# thuasrv32 register map
Vendor: jesseopdenbrouw; Series: RISC-V; File version: 0.4.1
CPU: THUASRV32 r2p1, little endian, no MPU, no FPU, 4 interrupt priority bits
Registers are 32-bit, read-write, no defined reset value unless marked. A register's access mark holds for its fields unless they carry their own. Offsets are from the block's base; [hi:lo] are bit positions.

## MSI — Machine Software Interrupt
Base 0xF0000900
0x00 TRIG — Trigger Register
  [0] MSI_TRIG — MSI Trigger Field

## SPI1 — Serial Peripheral interface 1
Base 0xF0000400
Same registers: SPI2 0xF0000500
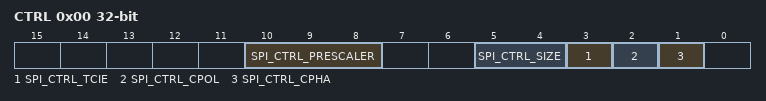
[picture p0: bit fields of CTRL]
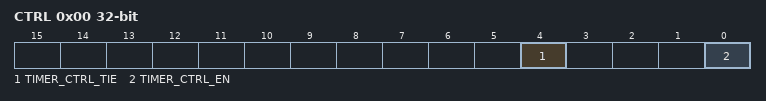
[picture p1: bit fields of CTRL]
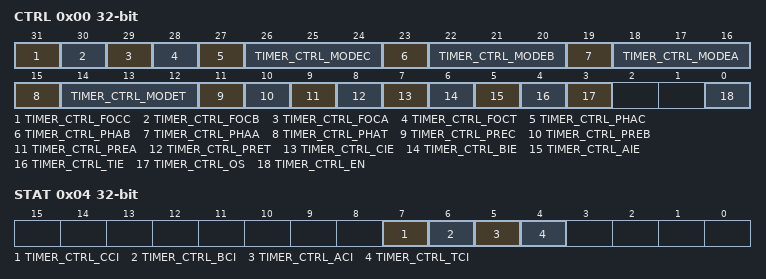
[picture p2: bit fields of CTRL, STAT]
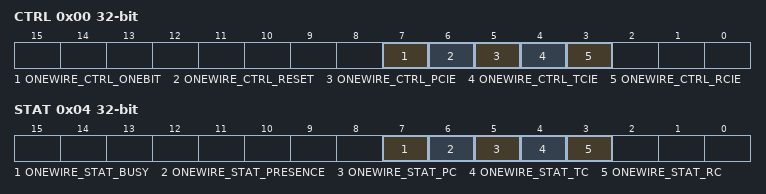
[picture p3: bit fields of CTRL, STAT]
0x00 CTRL — Control Register
  [10:8] SPI_CTRL_PRESCALER — SPI Prescaler
  [5:4] SPI_CTRL_SIZE — SPI Transmission Size
  [3] SPI_CTRL_TCIE — SPI Transmission Complete Interrupt Enable
  [2] SPI_CTRL_CPOL — SPI Clock Polarity
  [1] SPI_CTRL_CPHA — SPI Clock Phase
0x04 STAT — Status Register
  [3] SPI_STAT_TC — SPI Transmission Complete
0x08 DATA
  [31:0] SPI_DATA_DATA — SPI Data Field

## TIMER1
Base 0xF0000600
0x00 CTRL — Control Register
  [4] TIMER_CTRL_TIE — Timer 1 Compare Match Interrupt Enable
  [0] TIMER_CTRL_EN — Timer 1 Enable
0x04 STAT — Status Register
  [4] TIMER_STAT_TCI — Timer 1 Compare Match Interrupt
0x08 CNTR — Counter Register
0x0C CMPT — Compare Match T register

## TIMER2
Base 0xF0000700
0x00 CTRL — Control Register
  [31] TIMER_CTRL_FOCC — Timer 2 Force Compare Match C
  [30] TIMER_CTRL_FOCB — Timer 2 Force Compare Match B
  [29] TIMER_CTRL_FOCA — Timer 2 Force Compare Match A
  [28] TIMER_CTRL_FOCT — Timer 2 Force Compare Match T
  [27] TIMER_CTRL_PHAC — Timer 2 C Phase
  [26:24] TIMER_CTRL_MODEC — Timer 2 C Mode Field
  [23] TIMER_CTRL_PHAB — Timer 2 B Phase
  [22:20] TIMER_CTRL_MODEB — Timer 2 B Mode Field
  [19] TIMER_CTRL_PHAA — Timer 2 A Phase
  [18:16] TIMER_CTRL_MODEA — Timer 2 A Mode Field
  [15] TIMER_CTRL_PHAT — Timer 2 T Phase
  [14:12] TIMER_CTRL_MODET — Timer 2 T Mode Field
  [11] TIMER_CTRL_PREC — Timer 2 Preload C Enable
  [10] TIMER_CTRL_PREB — Timer 2 Preload B Enable
  [9] TIMER_CTRL_PREA — Timer 2 Preload A Enable
  [8] TIMER_CTRL_PRET — Timer 2 Preload T Enable
  [7] TIMER_CTRL_CIE — Timer 2 Compare Match C Interrupt Enable
  [6] TIMER_CTRL_BIE — Timer 2 Compare Match B Interrupt Enable
  [5] TIMER_CTRL_AIE — Timer 2 Compare Match A Interrupt Enable
  [4] TIMER_CTRL_TIE — Timer 2 Compare Match T Interrupt Enable
  [3] TIMER_CTRL_OS — Timer 2 One Shot
  [0] TIMER_CTRL_EN — Timer 2 Enable
0x04 STAT — Status Register
  [7] TIMER_CTRL_CCI — Timer 2 Compare Match C Interrupt
  [6] TIMER_CTRL_BCI — Timer 2 Compare Match B Interrupt
  [5] TIMER_CTRL_ACI — Timer 2 Compare Match A Interrupt
  [4] TIMER_CTRL_TCI — Timer 2 Compare Match T Interrupt
0x08 CNTR — Counter Register
  [15:0] TIMER_CNTR_CNTR — Timer 2 Counter Register
0x0C CMPT — Compare Match T Register
  [15:0] TIMER_CMPT_CMPT — Timer 2 Compare Match T Register
0x10 PSRC — Prescaler Register
  [15:0] TIMER_PRSC_PRSC — Timer 2 Prescaler Register
0x14 CMPA — Compare Match A Register
  [15:0] TIMER_CMPA_CMPA — Timer 2 Compare Match A Register
0x18 CMPB — Compare Match B Register
  [15:0] TIMER_CMPB_CMPB — Timer 2 Compare Match B Register
0x1C CMPC — Compare Match C Register
  [15:0] TIMER_CMPC_CMPC — Timer 2 Compare Match C Register

## CRC — Cyclic Redundancy Check Module
Base 0xF0000C00
0x00 CTRL — Control Register
  [5:4] CRC_CTRL_SIZE — CRC Size Field
0x04 STAT — Status Register
  [3] CRC_STAT_TC — CRC Transaction Complete
0x08 POLY — Polynomal Register
  [31:0] CRC_POLY_POLY — CRC Polynomal Register
0x0C SREG — CRC Calculation Register
  [31:0] CRC_SREG_SREG — CRC Calculated CRC Register
0x1C DATA — CRC Data Register
  [7:0] CRC_DATA_DATA

## ONEWIRE1 — 1-Wire Module 1
Base 0xF0000D00
0x00 CTRL — Control Register
  [7] ONEWIRE_CTRL_ONEBIT — Set One Bit Transmission Mode
  [6] ONEWIRE_CTRL_RESET — Start Reset Sequence
  [5] ONEWIRE_CTRL_PCIE — Presence Complete Interrupt Enable
  [4] ONEWIRE_CTRL_TCIE — Onewire Transmit Interrupt Enable
  [3] ONEWIRE_CTRL_RCIE — Onewire Receive Interrupt Enable
0x04 STAT — Status Register
  [7] ONEWIRE_STAT_BUSY — Busy
  [6] ONEWIRE_STAT_PRESENCE — Presence Detected
  [5] ONEWIRE_STAT_PC — Presence Complete
  [4] ONEWIRE_STAT_TC — Transmit Complete
  [3] ONEWIRE_STAT_RC — Receive Complete
0x08 DATA
  [7:0] ONEWIRE_DATA_DATA
0x0C READ — Start Read Register
  [?] ONEWIRE_READ_READ
